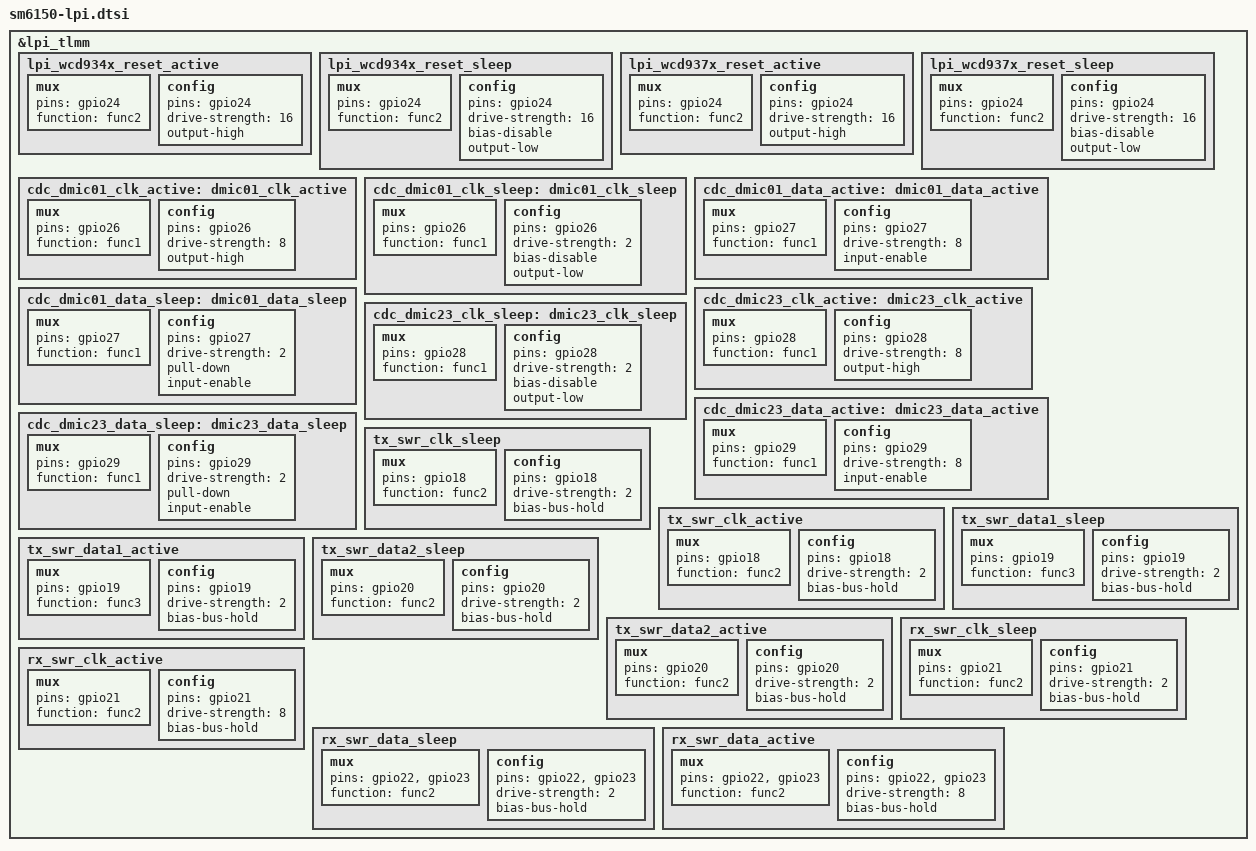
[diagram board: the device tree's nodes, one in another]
// SPDX-License-Identifier: BSD-3-Clause
/*
 * Copyright (c) Qualcomm Technologies, Inc. and/or its subsidiaries.
 */


&lpi_tlmm {

		lpi_wcd934x_reset_active: lpi_wcd934x_reset_active {
			mux {
				pins = "gpio24";
				function = "func2";
			};
			config {
				pins = "gpio24";
				drive-strength = <16>;
				output-high;
			};
		};

		lpi_wcd934x_reset_sleep: lpi_wcd934x_reset_sleep {
			mux {
				pins = "gpio24";
				function = "func2";
			};

			config {
				pins = "gpio24";
				drive-strength = <16>;
				bias-disable;
				output-low;
			};
		};

		lpi_wcd937x_reset_active: lpi_wcd937x_reset_active {
			mux {
				pins = "gpio24";
				function = "func2";
			};
			config {
				pins = "gpio24";
				drive-strength = <16>;
				output-high;
			};
		};

		lpi_wcd937x_reset_sleep: lpi_wcd937x_reset_sleep {
			mux {
				pins = "gpio24";
				function = "func2";
			};

			config {
				pins = "gpio24";
				drive-strength = <16>;
				bias-disable;
				output-low;
			};
		};

		cdc_dmic01_clk_active: dmic01_clk_active {
			mux {
				pins = "gpio26";
				function = "func1";
			};

			config {
				pins = "gpio26";
				drive-strength = <8>;
				output-high;
			};
		};

		cdc_dmic01_clk_sleep: dmic01_clk_sleep {
			mux {
				pins = "gpio26";
				function = "func1";
			};

			config {
				pins = "gpio26";
				drive-strength = <2>;
				bias-disable;
				output-low;
			};
		};

		cdc_dmic01_data_active: dmic01_data_active {
			mux {
				pins = "gpio27";
				function = "func1";
			};

			config {
				pins = "gpio27";
				drive-strength = <8>;
				input-enable;
			};
		};

		cdc_dmic01_data_sleep: dmic01_data_sleep {
			mux {
				pins = "gpio27";
				function = "func1";
			};

			config {
				pins = "gpio27";
				drive-strength = <2>;
				pull-down;
				input-enable;
			};
		};

		cdc_dmic23_clk_active: dmic23_clk_active {
			mux {
				pins = "gpio28";
				function = "func1";
			};

			config {
				pins = "gpio28";
				drive-strength = <8>;
				output-high;
			};
		};

		cdc_dmic23_clk_sleep: dmic23_clk_sleep {
			mux {
				pins = "gpio28";
				function = "func1";
			};

			config {
				pins = "gpio28";
				drive-strength = <2>;
				bias-disable;
				output-low;
			};
		};

		cdc_dmic23_data_active: dmic23_data_active {
			mux {
				pins = "gpio29";
				function = "func1";
			};

			config {
				pins = "gpio29";
				drive-strength = <8>;
				input-enable;
			};
		};

		cdc_dmic23_data_sleep: dmic23_data_sleep {
			mux {
				pins = "gpio29";
				function = "func1";
			};

			config {
				pins = "gpio29";
				drive-strength = <2>;
				pull-down;
				input-enable;
			};
		};

		tx_swr_clk_sleep: tx_swr_clk_sleep {
			mux {
				pins = "gpio18";
				function = "func2";
			};

			config {
				pins = "gpio18";
				drive-strength = <2>;
				bias-bus-hold;
			};
		};

		tx_swr_clk_active: tx_swr_clk_active {
			mux {
				pins = "gpio18";
				function = "func2";
			};

			config {
				pins = "gpio18";
				drive-strength = <2>;
				bias-bus-hold;
			};
		};

		tx_swr_data1_sleep: tx_swr_data1_sleep {
			mux {
				pins = "gpio19";
				function = "func3";
			};

			config {
				pins = "gpio19";
				drive-strength = <2>;
				bias-bus-hold;
			};
		};

		tx_swr_data1_active: tx_swr_data1_active {
			mux {
				pins = "gpio19";
				function = "func3";
			};

			config {
				pins = "gpio19";
				drive-strength = <2>;
				bias-bus-hold;
			};
		};

		tx_swr_data2_sleep: tx_swr_data2_sleep {
			mux {
				pins = "gpio20";
				function = "func2";
			};

			config {
				pins = "gpio20";
				drive-strength = <2>;
				bias-bus-hold;
			};
		};

		tx_swr_data2_active: tx_swr_data2_active {
			mux {
				pins = "gpio20";
				function = "func2";
			};

			config {
				pins = "gpio20";
				drive-strength = <2>;
				bias-bus-hold;
			};
		};

		rx_swr_clk_sleep: rx_swr_clk_sleep {
			mux {
				pins = "gpio21";
				function = "func2";
			};

			config {
				pins = "gpio21";
				drive-strength = <2>;
				bias-bus-hold;
			};
		};

		rx_swr_clk_active: rx_swr_clk_active {
			mux {
				pins = "gpio21";
				function = "func2";
			};

			config {
				pins = "gpio21";
				drive-strength = <8>;
				bias-bus-hold;
			};
		};

		rx_swr_data_sleep: rx_swr_data_sleep {
			mux {
				pins = "gpio22", "gpio23";
				function = "func2";
			};

			config {
				pins = "gpio22", "gpio23";
				drive-strength = <2>;
				bias-bus-hold;
			};
		};

		rx_swr_data_active: rx_swr_data_active {
			mux {
				pins = "gpio22", "gpio23";
				function = "func2";
			};

			config {
				pins = "gpio22", "gpio23";
				drive-strength = <8>;
				bias-bus-hold;
			};
		};
	};

